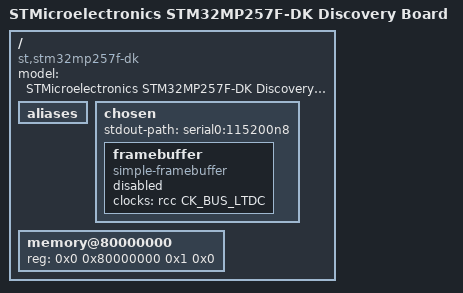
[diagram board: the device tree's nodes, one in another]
// SPDX-License-Identifier: (GPL-2.0-or-later OR BSD-3-Clause)
/*
 * Copyright (C) STMicroelectronics 2023 - All Rights Reserved
 * Author: Alexandre Torgue <alexandre.torgue@foss.st.com> for STMicroelectronics.
 */

/dts-v1/;

#include "stm32mp257.dtsi"
#include "stm32mp25xf.dtsi"
#include "stm32mp25-pinctrl.dtsi"
#include "stm32mp25xxal-pinctrl.dtsi"

/ {
	model = "STMicroelectronics STM32MP257F-DK Discovery Board";
	compatible = "st,stm32mp257f-dk", "st,stm32mp257";

	aliases {
	};

	chosen {
		stdout-path = "serial0:115200n8";
		#address-cells = <2>;
		#size-cells = <2>;
		ranges;

		framebuffer {
			compatible = "simple-framebuffer";
			clocks = <&rcc CK_BUS_LTDC>;
			status = "disabled";
		};
	};

	memory@80000000 {
		device_type = "memory";
		reg = <0x0 0x80000000 0x1 0x0>;
	};
};
